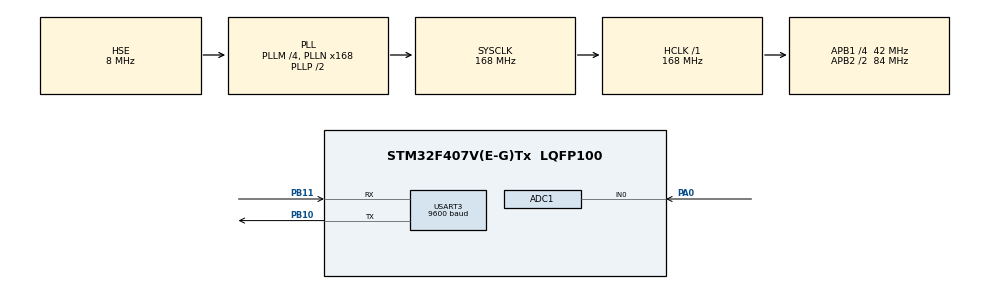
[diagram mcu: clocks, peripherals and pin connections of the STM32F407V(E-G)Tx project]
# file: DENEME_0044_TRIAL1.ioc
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Mcu.Family=STM32F4
RCC.PLLSourceVirtual=RCC_PLLSOURCE_HSE
PH0-OSC_IN.Signal=RCC_OSC_IN
RCC.CortexFreq_Value=168000000
ADC1.Rank-0\#ChannelRegularConversion=1
PB10.Mode=Asynchronous
ADC1.ContinuousConvMode=ENABLE
RCC.APB1CLKDivider=RCC_HCLK_DIV4
PB11.Signal=USART3_RX
RCC.SYSCLKSource=RCC_SYSCLKSOURCE_PLLCLK
ProjectManager.StackSize=0x400
PA0-WKUP.Signal=ADCx_IN0
USART3.BaudRate=9600
PB11.Mode=Asynchronous
ProjectManager.TargetToolchain=STM32CubeIDE
RCC.HCLKFreq_Value=168000000
RCC.APB2TimFreq_Value=168000000
ADC1.Channel-1\#ChannelRegularConversion=ADC_CHANNEL_VREFINT
RCC.LSE_VALUE=32768
RCC.AHBFreq_Value=168000000
PH0-OSC_IN.Mode=HSE-External-Oscillator
PB10.Signal=USART3_TX
ADC1.Channel-0\#ChannelRegularConversion=ADC_CHANNEL_0
RCC.HSE_VALUE=8000000
ADC1.ScanConvMode=ENABLE
board=custom
RCC.VCOOutputFreq_Value=336000000
VP_ADC1_Vref_Input.Mode=IN-Vrefint
RCC.APB2Freq_Value=84000000
PH1-OSC_OUT.Signal=RCC_OSC_OUT
SH.ADCx_IN0.0=ADC1_IN0,IN0
ADC1.NbrOfConversion=2
Mcu.Name=STM32F407V(E-G)Tx
ADC1.SamplingTime-0\#ChannelRegularConversion=ADC_SAMPLETIME_56CYCLES
PH1-OSC_OUT.Mode=HSE-External-Oscillator
RCC.48MHZClocksFreq_Value=84000000
ADC1.SamplingTime-1\#ChannelRegularConversion=ADC_SAMPLETIME_56CYCLES
RCC.SYSCLKFreq_VALUE=168000000
Mcu.Package=LQFP100
ADC1.master=1
USART3.VirtualMode=VM_ASYNC
ADC1.Rank-1\#ChannelRegularConversion=2
ProjectManager.HeapSize=0x200
RCC.HSI_VALUE=16000000
NVIC.PriorityGroup=NVIC_PRIORITYGROUP_4
ADC1.NbrOfConversionFlag=1
RCC.APB2CLKDivider=RCC_HCLK_DIV2
RCC.PLLM=4
RCC.PLLN=168
RCC.APB1TimFreq_Value=84000000
RCC.APB1Freq_Value=42000000

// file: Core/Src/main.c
/* USER CODE BEGIN Header */
/**
  ******************************************************************************
  * @file           : main.c
  * @brief          : Main program body
  ******************************************************************************
  * @attention
  *
  * <h2><center>&copy; Copyright (c) 2021 STMicroelectronics.
  * All rights reserved.</center></h2>
  *
  * This software component is licensed by ST under BSD 3-Clause license,
  * the "License"; You may not use this file except in compliance with the
  * License. You may obtain a copy of the License at:
  *                        opensource.org/licenses/BSD-3-Clause
  *
  ******************************************************************************
  */
/* USER CODE END Header */
#include "main.h"

/* USER CODE BEGIN Includes */
#include "stdio.h"
#include "string.h"
#include "stdlib.h"
/* USER CODE END Includes */

ADC_HandleTypeDef hadc1;

UART_HandleTypeDef huart3;

void SystemClock_Config(void);
static void MX_GPIO_Init(void);
static void MX_ADC1_Init(void);
static void MX_USART3_UART_Init(void);

/* USER CODE BEGIN 0 */

#define Vrefin_cal ((uint16_t *)((uint32_t)0x1FFF7A2A))

char data[5] ;
uint16_t adc_value[2] ;
uint8_t count = 0 ;
float temp ;
float temp_volt ;
float Vdda ;

void GET_ADC_VALUE()
{
	HAL_ADC_Start(&hadc1);
	if(HAL_ADC_PollForConversion(&hadc1, 2000) == HAL_OK)
	{
		adc_value[count] = HAL_ADC_GetValue(&hadc1);

		count += 1;

		if (count == 2 ) count = 0 ;
	}
	  //adc_value[0] = lm35 -----> RANK1
	  //adc_value[1] = Vrefin_data -------> RANK2
	  Vdda = 3.3 * (*Vrefin_cal / (float)adc_value[1]) ;

	  temp_volt = (adc_value[0] / 4095.0) * (Vdda*1000) ;

	  temp = temp_volt / 10 ;

}

void SEND_DATA_TO_PC()
{
	char data1[100] = "Ambient Temperature is " ;

	//HAL_UART_Transmit(&huart3, (uint8_t *)data1, strlen(data1), 250);
	//HAL_Delay(500);

	itoa(temp,data,10); // convert int to str

	strcat(data1,data); // add data to the end of data1
	strcat(data1," degrees  \n");

	//HAL_UART_Transmit(&huart3, (uint8_t *)data, strlen(data), 250);
	//HAL_Delay(500);

	//HAL_UART_Transmit(&huart3, (uint8_t* )data2, strlen(data2), 250);
	//HAL_Delay(500);

	HAL_UART_Transmit(&huart3, (uint8_t *)data1, sizeof(data1), 500);
	HAL_Delay(500);

}

/* USER CODE END 0 */

int main(void)
{

  /* MCU Configuration--------------------------------------------------------*/

  /* Reset of all peripherals, Initializes the Flash interface and the Systick. */
  HAL_Init();

  /* Configure the system clock */
  SystemClock_Config();

  /* Initialize all configured peripherals */
  MX_GPIO_Init();
  MX_ADC1_Init();
  MX_USART3_UART_Init();

  /* Infinite loop */
  while (1)
  {

    /* USER CODE BEGIN 3 */
	  GET_ADC_VALUE();
	  SEND_DATA_TO_PC();

  }
  /* USER CODE END 3 */
}

void SystemClock_Config(void)
{
  RCC_OscInitTypeDef RCC_OscInitStruct = {0};
  RCC_ClkInitTypeDef RCC_ClkInitStruct = {0};

  /** Configure the main internal regulator output voltage
  */
  __HAL_RCC_PWR_CLK_ENABLE();
  __HAL_PWR_VOLTAGESCALING_CONFIG(PWR_REGULATOR_VOLTAGE_SCALE1);
  /** Initializes the RCC Oscillators according to the specified parameters
  * in the RCC_OscInitTypeDef structure.
  */
  RCC_OscInitStruct.OscillatorType = RCC_OSCILLATORTYPE_HSE;
  RCC_OscInitStruct.HSEState = RCC_HSE_ON;
  RCC_OscInitStruct.PLL.PLLState = RCC_PLL_ON;
  RCC_OscInitStruct.PLL.PLLSource = RCC_PLLSOURCE_HSE;
  RCC_OscInitStruct.PLL.PLLM = 4;
  RCC_OscInitStruct.PLL.PLLN = 168;
  RCC_OscInitStruct.PLL.PLLP = RCC_PLLP_DIV2;
  RCC_OscInitStruct.PLL.PLLQ = 4;
  if (HAL_RCC_OscConfig(&RCC_OscInitStruct) != HAL_OK)
  {
    Error_Handler();
  }
  /** Initializes the CPU, AHB and APB buses clocks
  */
  RCC_ClkInitStruct.ClockType = RCC_CLOCKTYPE_HCLK|RCC_CLOCKTYPE_SYSCLK
                              |RCC_CLOCKTYPE_PCLK1|RCC_CLOCKTYPE_PCLK2;
  RCC_ClkInitStruct.SYSCLKSource = RCC_SYSCLKSOURCE_PLLCLK;
  RCC_ClkInitStruct.AHBCLKDivider = RCC_SYSCLK_DIV1;
  RCC_ClkInitStruct.APB1CLKDivider = RCC_HCLK_DIV4;
  RCC_ClkInitStruct.APB2CLKDivider = RCC_HCLK_DIV2;

  if (HAL_RCC_ClockConfig(&RCC_ClkInitStruct, FLASH_LATENCY_5) != HAL_OK)
  {
    Error_Handler();
  }
}

static void MX_ADC1_Init(void)
{

  ADC_ChannelConfTypeDef sConfig = {0};

  /** Configure the global features of the ADC (Clock, Resolution, Data Alignment and number of conversion)
  */
  hadc1.Instance = ADC1;
  hadc1.Init.ClockPrescaler = ADC_CLOCK_SYNC_PCLK_DIV4;
  hadc1.Init.Resolution = ADC_RESOLUTION_12B;
  hadc1.Init.ScanConvMode = ENABLE;
  hadc1.Init.ContinuousConvMode = ENABLE;
  hadc1.Init.DiscontinuousConvMode = DISABLE;
  hadc1.Init.ExternalTrigConvEdge = ADC_EXTERNALTRIGCONVEDGE_NONE;
  hadc1.Init.ExternalTrigConv = ADC_SOFTWARE_START;
  hadc1.Init.DataAlign = ADC_DATAALIGN_RIGHT;
  hadc1.Init.NbrOfConversion = 2;
  hadc1.Init.DMAContinuousRequests = DISABLE;
  hadc1.Init.EOCSelection = ADC_EOC_SINGLE_CONV;
  if (HAL_ADC_Init(&hadc1) != HAL_OK)
  {
    Error_Handler();
  }
  /** Configure for the selected ADC regular channel its corresponding rank in the sequencer and its sample time.
  */
  sConfig.Channel = ADC_CHANNEL_0;
  sConfig.Rank = 1;
  sConfig.SamplingTime = ADC_SAMPLETIME_56CYCLES;
  if (HAL_ADC_ConfigChannel(&hadc1, &sConfig) != HAL_OK)
  {
    Error_Handler();
  }
  /** Configure for the selected ADC regular channel its corresponding rank in the sequencer and its sample time.
  */
  sConfig.Channel = ADC_CHANNEL_VREFINT;
  sConfig.Rank = 2;
  if (HAL_ADC_ConfigChannel(&hadc1, &sConfig) != HAL_OK)
  {
    Error_Handler();
  }

}

static void MX_USART3_UART_Init(void)
{

  huart3.Instance = USART3;
  huart3.Init.BaudRate = 9600;
  huart3.Init.WordLength = UART_WORDLENGTH_8B;
  huart3.Init.StopBits = UART_STOPBITS_1;
  huart3.Init.Parity = UART_PARITY_NONE;
  huart3.Init.Mode = UART_MODE_TX_RX;
  huart3.Init.HwFlowCtl = UART_HWCONTROL_NONE;
  huart3.Init.OverSampling = UART_OVERSAMPLING_16;
  if (HAL_UART_Init(&huart3) != HAL_OK)
  {
    Error_Handler();
  }

}

static void MX_GPIO_Init(void)
{

  /* GPIO Ports Clock Enable */
  __HAL_RCC_GPIOH_CLK_ENABLE();
  __HAL_RCC_GPIOA_CLK_ENABLE();
  __HAL_RCC_GPIOB_CLK_ENABLE();

}

void Error_Handler(void)
{
  __disable_irq();
  while (1)
  {
  }
}

/************************ (C) COPYRIGHT STMicroelectronics *****END OF FILE****/
